# MAX32570 register map
Vendor: Maxim-Integrated; Series: ARMCM4; File version: 1.0
CPU: CM4 r2p1, little endian, MPU, FPU, 3 interrupt priority bits
Registers are 32-bit, read-write, reset 0x0 unless marked. A register's access mark holds for its fields unless they carry their own. Offsets are from the block's base; [hi:lo] are bit positions; {n}, {i} and the like mark numbered series.

## SIR — System Initialization Registers.
Base 0x40000400
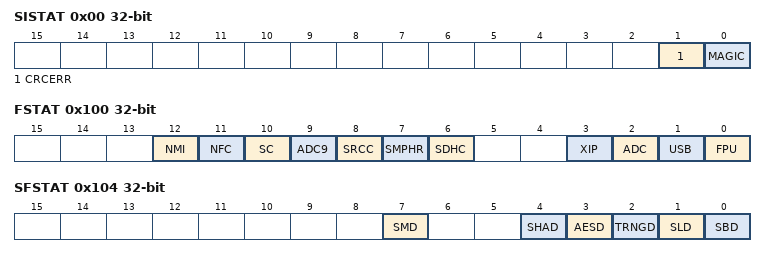
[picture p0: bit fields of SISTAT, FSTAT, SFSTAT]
0x00 SISTAT ro — System Initialization Status Register.
  [1] CRCERR — CRC Error Status. This bit is set by the system initialization block following power-up.
    on read: 0=noError (No CRC errors occurred during the read of the OTP memory block.); 1=error (A CRC error occurred while reading the OTP. The address of the failure location in the OTP memory is stored in the ERRADDR register.)
  [0] MAGIC — Magic Word Validation. This bit is set by the system initialization block following power-up.
    on read: 0=magicNotSet (Magic word was not set (OTP has not been initialized properly).); 1=magicSet (Magic word was set (OTP contains valid settings).)
0x04 ERRADDR ro — Read-only field set by the SIB block if a CRC error occurs during the read of the OTP memory. Contains the failing address in OTP memory (when CRCERR equals 1).
0x100 FSTAT ro — funcstat register.
  [all] fields
    0=no; 1=yes
  [12] NMI — NMI function.
  [11] NFC — NFC function.
  [10] SC — SC function.
  [9] ADC9 — ADC9 function.
  [8] SRCC — SRCC function.
  [7] SMPHR — SMPHR function.
  [6] SDHC — SDHC function.
  [3] XIP — XiP function.
  [2] ADC — 10-bit Sigma Delta ADC.
  [1] USB — USB Device.
  [0] FPU — FPU Function.
0x104 SFSTAT ro — secfuncstat register.
  [all] fields
    0=no; 1=yes
  [7] SMD — SMD function.
  [4] SHAD — SHA function.
  [3] AESD — AES function.
  [2] TRNGD — TRNG function.
  [1] SLD — SLD function.
  [0] SBD — SBD function.

## HA — Hardware Accelerator
Base 0x40036000
0x00 IP ro — Q30E Instruction Pointer.
0x04 SP ro — Q30E Stack Pointer.
0x08 DP0 ro — Q30E Data Pointer 0.
0x0C DP1 ro — Q30E Data Pointer 1.
0x10 BP ro — Q30E Frame Pointer Base.
0x14 OFFS ro — Q30E Frame Pointer Offset.
0x18 LC0 ro — Q30E Loop Counter 0.
0x1C LC1 ro — Q30E Loop Counter 1.
{0x20+4i} A{i} ro (i=0..3) — Q30E Accumulator {i}.
0x30 WDCN ro — Q30E Watchdog Control.
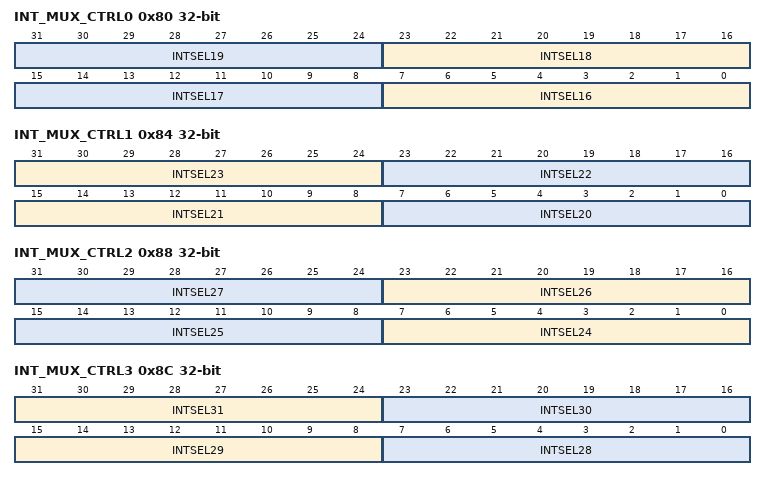
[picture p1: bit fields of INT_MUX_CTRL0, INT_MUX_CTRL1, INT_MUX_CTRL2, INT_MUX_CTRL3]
0x80 INT_MUX_CTRL0 — Interrupt Mux Control 0.
  [8n-121:8n-128] INTSEL{n} (n=16..19) — Interrupt Selection For {n}th Interrupt.
0x84 INT_MUX_CTRL1 — Interrupt Mux Control 1.
  [31:24] INTSEL23 — Interrupt Selection For 23rd Interrupt.
  [23:16] INTSEL22 — Interrupt Selection For 22nd Interrupt.
  [15:8] INTSEL21 — Interrupt Selection For 21st Interrupt.
  [7:0] INTSEL20 — Interrupt Selection For 20th Interrupt.
0x88 INT_MUX_CTRL2 — Interrupt Mux Control 2.
  [8n-185:8n-192] INTSEL{n} (n=24..27) — Interrupt Selection For {n}th Interrupt.
0x8C INT_MUX_CTRL3 — Interrupt Mux Control 3.
  [31:24] INTSEL31 — Interrupt Selection For 31st Interrupt.
  [23:16] INTSEL30 — Interrupt Selection For 30th Interrupt.
  [15:8] INTSEL29 — Interrupt Selection For 29th Interrupt.
  [7:0] INTSEL28 — Interrupt Selection For 28th Interrupt.
0x90 IP_ADDR — Configurable starting IP address for Q30E.
  [31:0] START_IP_ADDR — Starting IP address for Q30E
0x94 CTRL — Control Register.
  [0] EN — Enable SDMA.
    0=dis (Disable SDMA.); 1=en (Enable SDMA.)
0xA0 INT_IN_CTRL — Interrupt Input From CPU Control Register.
  [0] INTSET — Set Interrupt Flag.
    0=dis (Set interrupt Flag to 0.); 1=set (Set Interrupt Flag to 1.)
0xA4 INT_IN_FLAG — Interrupt Input From CPU Flag.
  [0] INTFLAG — Interrupt Flag.
    0=No Effect; 1=clear (INT_IN_FLAG =0)
0xA8 INT_IN_IE — Interrupt Input From CPU Enable.
  [0] INT_IN_EN — Interrupt Enable.
0xB0 IRQ_FLAG — Interrupt Output To CPU Flag.
  [0] IRQ_FLAG — Interrupt Flag.
0xB4 IRQ_IE — Interrupt Output To CPU Control Register.
  [0] IRQ_EN — Interrupt Enable.

## SEMA — The Semaphore peripheral allows multiple cores in a system to cooperate when accessing shred resources. The peripheral contains eight semaphores that can be atomically set and cleared. It is left to the discretion of the software architect to decide how and when the semaphores are used and how they are allocated. Existing hardware does not have to be modified for this type of cooperative sharing, and the use of semaphores is exclusively within the software domain.
Base 0x4003E000
{0x0+4i} SEMAPHORES[{i}] (i=0..7) — Read to test and set, returns prior value. Write 0 to clear semaphore.
  [0] sema
0x100 status — Semaphore status bits. 0 indicates the semaphore is free, 1 indicates taken.
  [7:0] STATUS
